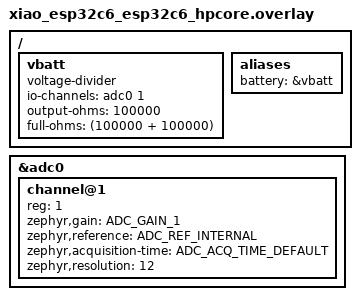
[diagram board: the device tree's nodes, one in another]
/*
 * SPDX-FileCopyrightText: Copyright The Zephyr Project Contributors
 * SPDX-License-Identifier: Apache-2.0
 */

#include <zephyr/dt-bindings/gpio/gpio.h>

/ {
	vbatt: vbatt {
		compatible = "voltage-divider";
		io-channels = <&adc0 1>;
		output-ohms = <100000>;
		full-ohms = <(100000 + 100000)>;
	};

	aliases {
		battery = &vbatt;
	};
};

&adc0 {
	#address-cells = <1>;
	#size-cells = <0>;
	status = "okay";

	channel@1 {
		reg = <1>;
		zephyr,gain = "ADC_GAIN_1";
		zephyr,reference = "ADC_REF_INTERNAL";
		zephyr,acquisition-time = <ADC_ACQ_TIME_DEFAULT>;
		zephyr,resolution = <12>;
	};
};
